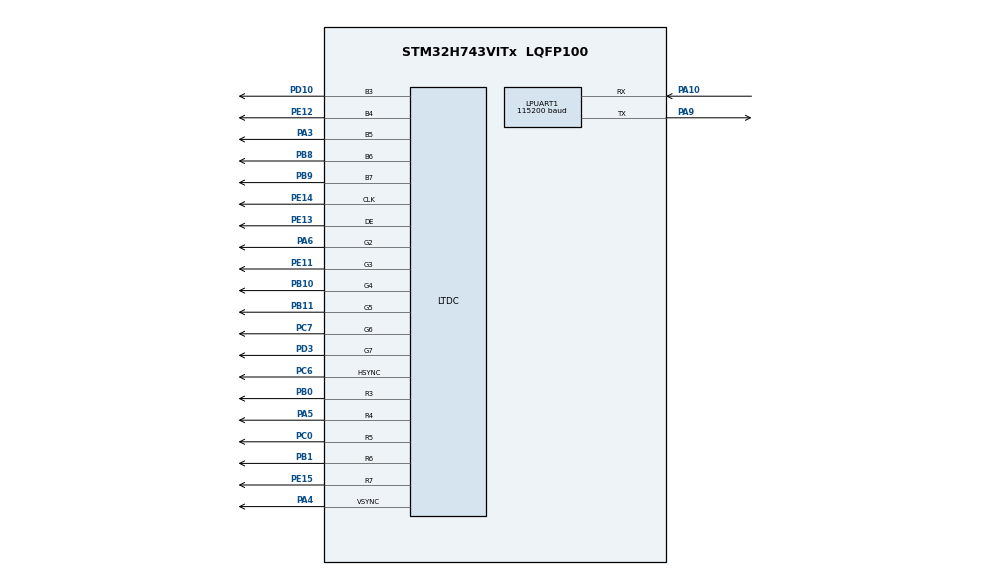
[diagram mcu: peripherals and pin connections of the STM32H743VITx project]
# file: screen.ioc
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CORTEX_M7.AccessPermission_S-Cortex_Memory_Protection_Unit_Region1_Settings_S=MPU_REGION_FULL_ACCESS
CORTEX_M7.AccessPermission_Spec=MPU_REGION_FULL_ACCESS
CORTEX_M7.BaseAddress_S-Cortex_Memory_Protection_Unit_Region1_Settings_S=0x40000000
CORTEX_M7.BaseAddress_Spec=0x24000000
CORTEX_M7.CPU_DCache=Enabled
CORTEX_M7.CPU_ICache=Enabled
CORTEX_M7.DisableExec_S-Cortex_Memory_Protection_Unit_Region1_Settings_S=MPU_INSTRUCTION_ACCESS_DISABLE
CORTEX_M7.DisableExec_Spec=MPU_INSTRUCTION_ACCESS_ENABLE
CORTEX_M7.Enable_S-Cortex_Memory_Protection_Unit_Region1_Settings_S=MPU_REGION_ENABLE
CORTEX_M7.IsBufferable_Spec=MPU_ACCESS_BUFFERABLE
CORTEX_M7.IsCacheable_Spec=MPU_ACCESS_CACHEABLE
CORTEX_M7.IsShareable_S-Cortex_Memory_Protection_Unit_Region1_Settings_S=MPU_ACCESS_SHAREABLE
CORTEX_M7.Size_S-Cortex_Memory_Protection_Unit_Region1_Settings_S=MPU_REGION_SIZE_512MB
CORTEX_M7.Size_Spec=MPU_REGION_SIZE_2MB
CORTEX_M7.SubRegionDisable_Spec=0x00
CORTEX_M7.default_mode_Activation=1
DMA2D.ColorMode=DMA2D_OUTPUT_RGB565
DMA2D.Mode=DMA2D_R2M
LPUART1.BaudRate=115200
LTDC.ActiveH=272
LTDC.ActiveW=480
LTDC.Alpha_L0=255
LTDC.FBStartAdress_L0=(uint32_t)FillBuf
LTDC.HBP=43
LTDC.HFP=8
LTDC.HSync=1
LTDC.ImageHeight_L0=272
LTDC.ImageWidth_L0=480
LTDC.Layers=0
LTDC.PixelFormat_L0=LTDC_PIXEL_FORMAT_RGB565
LTDC.VBP=12
LTDC.VFP=8
LTDC.VSync=1
LTDC.WindowX1_L0=480
LTDC.WindowY1_L0=272
Mcu.Family=STM32H7
Mcu.Name=STM32H743VITx
Mcu.Package=LQFP100
NVIC.LTDC_IRQn=true\:0\:0\:false\:false\:true\:true\:true\:true
NVIC.PriorityGroup=NVIC_PRIORITYGROUP_4
PA10.Mode=Asynchronous
PA10.Signal=LPUART1_RX
PA13\ (JTMS/SWDIO).Mode=Serial_Wire
PA13\ (JTMS/SWDIO).Signal=DEBUG_JTMS-SWDIO
PA14\ (JTCK/SWCLK).Mode=Serial_Wire
PA14\ (JTCK/SWCLK).Signal=DEBUG_JTCK-SWCLK
PA3.GPIO_Speed=GPIO_SPEED_FREQ_VERY_HIGH
PA3.Mode=RGB565
PA3.Signal=LTDC_B5
PA4.GPIO_Speed=GPIO_SPEED_FREQ_VERY_HIGH
PA4.Mode=RGB565
PA4.Signal=LTDC_VSYNC
PA5.GPIO_Speed=GPIO_SPEED_FREQ_VERY_HIGH
PA5.Mode=RGB565
PA5.Signal=LTDC_R4
PA6.GPIO_Speed=GPIO_SPEED_FREQ_VERY_HIGH
PA6.Mode=RGB565
PA6.Signal=LTDC_G2
PA9.Mode=Asynchronous
PA9.Signal=LPUART1_TX
PB0.GPIO_Speed=GPIO_SPEED_FREQ_VERY_HIGH
PB0.Mode=RGB565
PB0.Signal=LTDC_R3
PB1.GPIO_Speed=GPIO_SPEED_FREQ_VERY_HIGH
PB1.Mode=RGB565
PB1.Signal=LTDC_R6
PB10.GPIO_Speed=GPIO_SPEED_FREQ_VERY_HIGH
PB10.Mode=RGB565
PB10.Signal=LTDC_G4
PB11.GPIO_Speed=GPIO_SPEED_FREQ_VERY_HIGH
PB11.Mode=RGB565
PB11.Signal=LTDC_G5
PB8.GPIO_Speed=GPIO_SPEED_FREQ_VERY_HIGH
PB8.Mode=RGB565
PB8.Signal=LTDC_B6
PB9.GPIO_Speed=GPIO_SPEED_FREQ_VERY_HIGH
PB9.Mode=RGB565
PB9.Signal=LTDC_B7
PC0.GPIO_Speed=GPIO_SPEED_FREQ_VERY_HIGH
PC0.Mode=RGB565
PC0.Signal=LTDC_R5
PC6.GPIO_Speed=GPIO_SPEED_FREQ_VERY_HIGH
PC6.Mode=RGB565
PC6.Signal=LTDC_HSYNC
PC7.GPIO_Speed=GPIO_SPEED_FREQ_VERY_HIGH
PC7.Mode=RGB565
PC7.Signal=LTDC_G6
PD10.GPIO_Speed=GPIO_SPEED_FREQ_VERY_HIGH
PD10.Mode=RGB565
PD10.Signal=LTDC_B3
PD3.GPIO_Speed=GPIO_SPEED_FREQ_VERY_HIGH
PD3.Mode=RGB565
PD3.Signal=LTDC_G7
PE11.GPIO_Speed=GPIO_SPEED_FREQ_VERY_HIGH
PE11.Mode=RGB565
PE11.Signal=LTDC_G3
PE12.GPIO_Speed=GPIO_SPEED_FREQ_VERY_HIGH
PE12.Mode=RGB565
PE12.Signal=LTDC_B4
PE13.GPIO_Speed=GPIO_SPEED_FREQ_VERY_HIGH
PE13.Mode=RGB565
PE13.Signal=LTDC_DE
PE14.GPIO_Speed=GPIO_SPEED_FREQ_VERY_HIGH
PE14.Mode=RGB565
PE14.Signal=LTDC_CLK
PE15.GPIO_Speed=GPIO_SPEED_FREQ_VERY_HIGH
PE15.Mode=RGB565
PE15.Signal=LTDC_R7
PH0-OSC_IN\ (PH0).Mode=HSE-External-Oscillator
PH0-OSC_IN\ (PH0).Signal=RCC_OSC_IN
PH1-OSC_OUT\ (PH1).Mode=HSE-External-Oscillator
PH1-OSC_OUT\ (PH1).Signal=RCC_OSC_OUT
ProjectManager.HeapSize=0x2000
ProjectManager.StackSize=0x4000
ProjectManager.TargetToolchain=MDK-ARM V5.32
RCC.ADCFreq_Value=50390625
RCC.APB1Freq_Value=80625000
RCC.APB2Freq_Value=80625000
RCC.APB3Freq_Value=80625000
RCC.APB4Freq_Value=80625000
RCC.CortexFreq_Value=322500000
RCC.D1PPRE=RCC_APB3_DIV2
RCC.D2PPRE1=RCC_APB1_DIV2
RCC.D2PPRE2=RCC_APB2_DIV2
RCC.D3PPRE=RCC_APB4_DIV2
RCC.DIVM1=5
RCC.DIVM3=5
RCC.DIVN3=192
RCC.DIVR3=60
RCC.HCLKFreq_Value=161250000
RCC.HPRE=RCC_HCLK_DIV2
RCC.PLL3FRACN=0
RCC.PLLSourceVirtual=RCC_PLLSOURCE_HSE
RCC.SYSCLKFreq_VALUE=322500000
RCC.SYSCLKSource=RCC_SYSCLKSOURCE_PLLCLK
RCC.USBFreq_Value=322500000
VP_DMA2D_VS_DMA2D.Mode=DMA2D_Activate
VP_MEMORYMAP_VS_MEMORYMAP.Mode=CurAppReg
board=custom

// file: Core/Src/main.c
/* USER CODE BEGIN Header */
/**
  ******************************************************************************
  * @file           : main.c
  * @brief          : Main program body
  ******************************************************************************
  * @attention
  *
  * Copyright (c) 2026 STMicroelectronics.
  * All rights reserved.
  *
  * This software is licensed under terms that can be found in the LICENSE file
  * in the root directory of this software component.
  * If no LICENSE file comes with this software, it is provided AS-IS.
  *
  ******************************************************************************
  */
/* USER CODE END Header */
#include "main.h"
#include "dma2d.h"
#include "usart.h"
#include "ltdc.h"
#include "memorymap.h"
#include "gpio.h"

/* USER CODE BEGIN Includes */

#include "porting/lv_port_disp.h"
#include "porting/lv_port_indev.h"
#include "lvgl.h"
#include "../../MDK-ARM/GT9XX.h"

/* USER CODE END Includes */

/* USER CODE BEGIN PTD */
__attribute__((aligned(32))) uint16_t FillBuf[480 * 272];
__attribute__((aligned(32))) uint16_t FillBuf2[480 * 272];

/* USER CODE END PTD */

void SystemClock_Config(void);
static void MPU_Config(void);
/* USER CODE BEGIN PFP */
/* USER CODE BEGIN PFP */

/* USER CODE END PFP */

int main(void)
{

  /* MPU Configuration--------------------------------------------------------*/
  MPU_Config();

  /* Enable the CPU Cache */

  /* Enable I-Cache---------------------------------------------------------*/
  SCB_EnableICache();

  /* Enable D-Cache---------------------------------------------------------*/
  SCB_EnableDCache();

  /* MCU Configuration--------------------------------------------------------*/

  /* Reset of all peripherals, Initializes the Flash interface and the Systick. */
  HAL_Init();

  /* Configure the system clock */
  SystemClock_Config();

  /* Initialize all configured peripherals */
  MX_GPIO_Init();
  MX_DMA2D_Init();
  MX_LTDC_Init();
  MX_LPUART1_UART_Init();
  /* USER CODE BEGIN 2 */

  __HAL_RCC_DMA2D_CLK_ENABLE();
  lv_init();

  lv_port_disp_init();
  lv_port_indev_init();

  // extern void lv_demo_stress(void);
  // lv_demo_stress();

  // extern void lv_demo_benchmark(void);
  // lv_demo_benchmark();

   extern void lv_demo_music(void);
   lv_demo_music();

//  extern void lv_demo_widgets(void);
//  lv_demo_widgets();

  /* USER CODE END 2 */

  /* Infinite loop */
  while (1)
  {

    /* USER CODE BEGIN 3 */

    lv_timer_handler(); // Increment LVGL tick count
    //HAL_Delay(5); // Delay for a short period to allow LVGL to process tasks

  }
  /* USER CODE END 3 */
}

void SystemClock_Config(void)
{
  RCC_OscInitTypeDef RCC_OscInitStruct = {0};
  RCC_ClkInitTypeDef RCC_ClkInitStruct = {0};

  /** Supply configuration update enable
  */
  HAL_PWREx_ConfigSupply(PWR_LDO_SUPPLY);

  /** Configure the main internal regulator output voltage
  */
  __HAL_PWR_VOLTAGESCALING_CONFIG(PWR_REGULATOR_VOLTAGE_SCALE1);

  while(!__HAL_PWR_GET_FLAG(PWR_FLAG_VOSRDY)) {}

  /** Initializes the RCC Oscillators according to the specified parameters
  * in the RCC_OscInitTypeDef structure.
  */
  RCC_OscInitStruct.OscillatorType = RCC_OSCILLATORTYPE_HSE;
  RCC_OscInitStruct.HSEState = RCC_HSE_ON;
  RCC_OscInitStruct.PLL.PLLState = RCC_PLL_ON;
  RCC_OscInitStruct.PLL.PLLSource = RCC_PLLSOURCE_HSE;
  RCC_OscInitStruct.PLL.PLLM = 5;
  RCC_OscInitStruct.PLL.PLLN = 129;
  RCC_OscInitStruct.PLL.PLLP = 2;
  RCC_OscInitStruct.PLL.PLLQ = 2;
  RCC_OscInitStruct.PLL.PLLR = 2;
  RCC_OscInitStruct.PLL.PLLRGE = RCC_PLL1VCIRANGE_2;
  RCC_OscInitStruct.PLL.PLLVCOSEL = RCC_PLL1VCOWIDE;
  RCC_OscInitStruct.PLL.PLLFRACN = 0;
  if (HAL_RCC_OscConfig(&RCC_OscInitStruct) != HAL_OK)
  {
    Error_Handler();
  }

  /** Initializes the CPU, AHB and APB buses clocks
  */
  RCC_ClkInitStruct.ClockType = RCC_CLOCKTYPE_HCLK|RCC_CLOCKTYPE_SYSCLK
                              |RCC_CLOCKTYPE_PCLK1|RCC_CLOCKTYPE_PCLK2
                              |RCC_CLOCKTYPE_D3PCLK1|RCC_CLOCKTYPE_D1PCLK1;
  RCC_ClkInitStruct.SYSCLKSource = RCC_SYSCLKSOURCE_PLLCLK;
  RCC_ClkInitStruct.SYSCLKDivider = RCC_SYSCLK_DIV1;
  RCC_ClkInitStruct.AHBCLKDivider = RCC_HCLK_DIV2;
  RCC_ClkInitStruct.APB3CLKDivider = RCC_APB3_DIV2;
  RCC_ClkInitStruct.APB1CLKDivider = RCC_APB1_DIV2;
  RCC_ClkInitStruct.APB2CLKDivider = RCC_APB2_DIV2;
  RCC_ClkInitStruct.APB4CLKDivider = RCC_APB4_DIV2;

  if (HAL_RCC_ClockConfig(&RCC_ClkInitStruct, FLASH_LATENCY_2) != HAL_OK)
  {
    Error_Handler();
  }
}

 /* MPU Configuration */

void MPU_Config(void)
{
  MPU_Region_InitTypeDef MPU_InitStruct = {0};

  /* Disables the MPU */
  HAL_MPU_Disable();

  /** Initializes and configures the Region and the memory to be protected
  */
  MPU_InitStruct.Enable = MPU_REGION_ENABLE;
  MPU_InitStruct.Number = MPU_REGION_NUMBER0;
  MPU_InitStruct.BaseAddress = 0x24000000;
  MPU_InitStruct.Size = MPU_REGION_SIZE_2MB;
  MPU_InitStruct.SubRegionDisable = 0x00;
  MPU_InitStruct.TypeExtField = MPU_TEX_LEVEL0;
  MPU_InitStruct.AccessPermission = MPU_REGION_FULL_ACCESS;
  MPU_InitStruct.DisableExec = MPU_INSTRUCTION_ACCESS_ENABLE;
  MPU_InitStruct.IsShareable = MPU_ACCESS_SHAREABLE;
  MPU_InitStruct.IsCacheable = MPU_ACCESS_CACHEABLE;
  MPU_InitStruct.IsBufferable = MPU_ACCESS_BUFFERABLE;

  HAL_MPU_ConfigRegion(&MPU_InitStruct);

  /** Initializes and configures the Region and the memory to be protected
  */
  MPU_InitStruct.Number = MPU_REGION_NUMBER1;
  MPU_InitStruct.BaseAddress = 0x40000000;
  MPU_InitStruct.Size = MPU_REGION_SIZE_512MB;
  MPU_InitStruct.SubRegionDisable = 0x0;
  MPU_InitStruct.DisableExec = MPU_INSTRUCTION_ACCESS_DISABLE;
  MPU_InitStruct.IsCacheable = MPU_ACCESS_NOT_CACHEABLE;
  MPU_InitStruct.IsBufferable = MPU_ACCESS_NOT_BUFFERABLE;

  HAL_MPU_ConfigRegion(&MPU_InitStruct);
  /* Enables the MPU */
  HAL_MPU_Enable(MPU_PRIVILEGED_DEFAULT);

}

void Error_Handler(void)
{
  __disable_irq();
  while (1)
  {
  }
}
